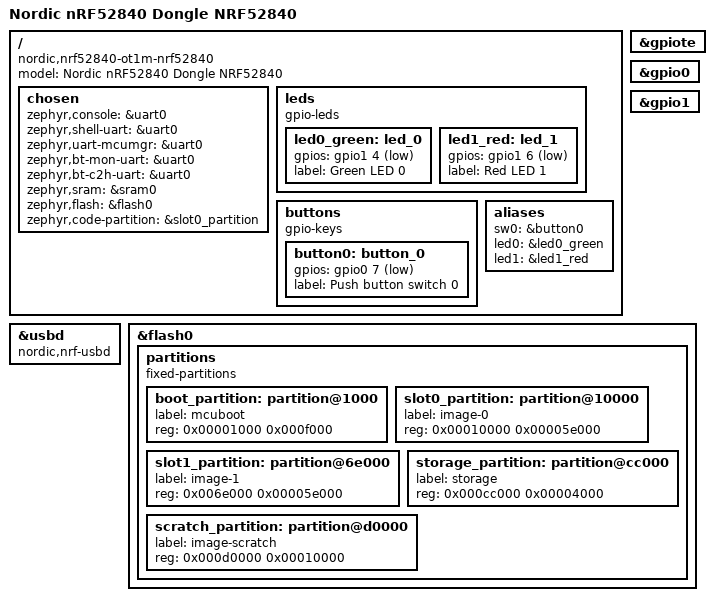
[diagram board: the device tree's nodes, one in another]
/*
 * Copyright (c) 2018 Nordic Semiconductor ASA
 * Copyright (c) 2017 Linaro Limited
 *
 * SPDX-License-Identifier: Apache-2.0
 */

/dts-v1/;
#include <nordic/nrf52840_qiaa.dtsi>

/ {
	model = "Nordic nRF52840 Dongle NRF52840";
	compatible = "nordic,nrf52840-ot1m-nrf52840";

	chosen {
		zephyr,console = &uart0;
		zephyr,shell-uart = &uart0;
		zephyr,uart-mcumgr = &uart0;
		zephyr,bt-mon-uart = &uart0;
		zephyr,bt-c2h-uart = &uart0;
		zephyr,sram = &sram0;
		zephyr,flash = &flash0;
		zephyr,code-partition = &slot0_partition;
	};

	leds {
		compatible = "gpio-leds";
		led0_green: led_0 {
			gpios = <&gpio1 4 GPIO_ACTIVE_LOW>;
			label = "Green LED 0";
		};
		led1_red: led_1 {
			gpios = <&gpio1 6 GPIO_ACTIVE_LOW>;
			label = "Red LED 1";
		};
	};

	buttons {
		compatible = "gpio-keys";
		button0: button_0 {
			gpios = <&gpio0 7 (GPIO_PULL_UP | GPIO_ACTIVE_LOW)>;
			label = "Push button switch 0";
		};
	};

	/* These aliases are provided for compatibility with samples */
	aliases {
		sw0 = &button0;
		led0 = &led0_green;
		led1 = &led1_red;
	};
};

&gpiote {
	status = "okay";
};

&gpio0 {
	status = "okay";
};

&gpio1 {
	status = "okay";
};

zephyr_udc0: &usbd {
	compatible = "nordic,nrf-usbd";
	status = "okay";
};

&flash0 {
	partitions {
		compatible = "fixed-partitions";
		#address-cells = <1>;
		#size-cells = <1>;

		/* MCUboot placed after Nordic MBR.
		 * The size of this partition ensures that MCUBoot
		 * can be built with CDC ACM support and w/o optimizations.
		 */
		boot_partition: partition@1000 {
			label = "mcuboot";
			reg = <0x00001000 0x000f000>;
		};

		slot0_partition: partition@10000 {
			label = "image-0";
			reg = <0x00010000 0x00005e000>;
		};
		slot1_partition: partition@6e000 {
			label = "image-1";
			reg = <0x006e000 0x00005e000>;
		};
		storage_partition: partition@cc000 {
			label = "storage";
			reg = <0x000cc000 0x00004000>;
		};
		scratch_partition: partition@d0000 {
			label = "image-scratch";
			reg = <0x000d0000 0x00010000>;
		};

		/* Nordic nRF5 bootloader <0xe0000 0x1c000>
		 *
		 * In addition, the last and second last flash pages
		 * are used by the nRF5 bootloader and MBR to store settings.
		 */
	};
};
